# RL7005_IP_SVD register map
Vendor: Realtek
Registers are 32-bit, read-write, reset 0x0 unless marked. A register's access mark holds for its fields unless they carry their own. Offsets are from the block's base; [hi:lo] are bit positions; lines under a group give offsets from that group; {n}, {i} and the like mark numbered series.

## LP_AON
Base 0x4080A000
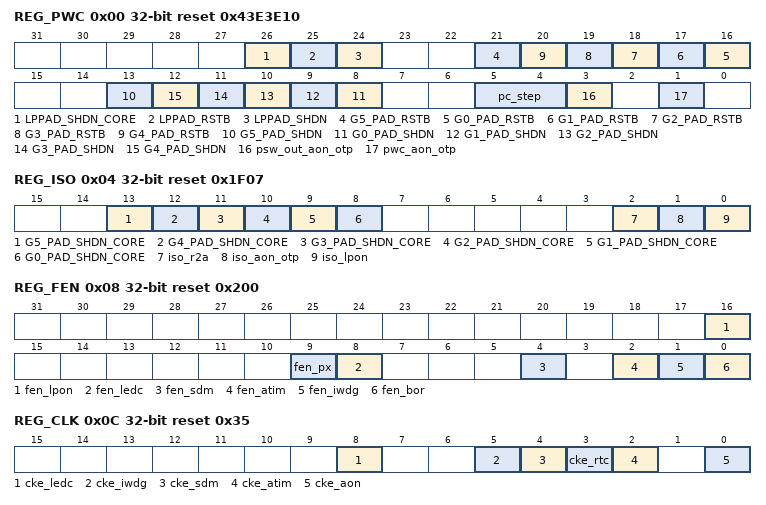
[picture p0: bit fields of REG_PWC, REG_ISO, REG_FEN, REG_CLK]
0x00 REG_PWC access per field reset 0x43E3E10
  [26] LPPAD_SHDN_CORE rw — 1: Release LP PAD SHDN CORE (except G5) 0: Global Assert LP PAD RSTB33 Note:G5 is aon pad, when all LP pad's IO power is ready , aon pmc will release this bit , only in power on init seq .
  [25] LPPAD_RSTB rw — 1: Release LP PAD RSTB33 (except G5) 0: Global Assert LP PAD RSTB33 Note: aon pmc will auto release this bit in power on init seq
  [24] LPPAD_SHDN rw — 1: Global Enable LP PAD (except G5) 0: Shutdown LP PAD Note: aon pmc will auto release this bit in power on init seq
  [21] G5_PAD_RSTB rw — 1: Enable G5 group pad 0: Reset PAD Note: This is AON pad group, direct connect to G5 pad, aon pmc will auto release this bit in power on init seq
  [n+16] G{n}_PAD_RSTB rw (n=0..4) — 1: Enable G{n} group pad 0: Reset PAD
  [13] G5_PAD_SHDN rw — 1: Enable G5 group pad 0: Shutdown PAD Note: This is AON pad group, aon pmc will auto release this bit in power on init seq
  [n+8] G{n}_PAD_SHDN rw (n=0..4) — 1: Enable G{n} group pad 0: Shutdown PAD
  [5:4] pc_step rw — power cut enable time step. 0: not valid 1: 10us 2: 20us 3: 30us
  [3] psw_out_aon_otp ro — aon otp domain power switch status 1: power on 0: power off
  [1] pwc_aon_otp rw — OTP power cut enable for core power, high active. 1:enable 0:disable
0x04 REG_ISO reset 0x1F07
  [13] G5_PAD_SHDN_CORE — 1: Enable G5 group pad 0: Shutdown PAD Note: This maybe nouse , for AON pad , IO power always on before core power.
  [12] G4_PAD_SHDN_CORE — 1: Enable G4 group pad 0: Shutdown PAD
  [11] G3_PAD_SHDN_CORE — 1: Enable G3 group pad 0: Shutdown PAD
  [10] G2_PAD_SHDN_CORE — 1: Enable G2 group pad 0: Shutdown PAD
  [9] G1_PAD_SHDN_CORE — 1: Enable G1 group pad 0: Shutdown PAD Note:default is shutdown, wait pmc enable MLDO power
  [8] G0_PAD_SHDN_CORE — 1: Enable G0 group pad 0: Shutdown PAD It will be deassert by aon_det_rtc automaticly
  [2] iso_r2a — 1: ISO signals from RTC to AON 0: Release
  [1] iso_aon_otp — 1: ISO signals from otp core power domain 0: Release
  [0] iso_lpon — When LDO core power on, PD_LPON is on. 1: ISO signal of LPON power domain 0: Release
0x08 REG_FEN reset 0x200
  [16] fen_lpon — LS global reset 1: Enable LS function 0: Disable
  [9] fen_px — 1: Enable pad interface function 0: Disable Note: this module is in syson power domain
  [8] fen_ledc — 1: Enable led display function 0: Disable Note: this module is in syson power domain
  [4] fen_sdm — 1: Enable 32.768K SDM function 0: Disable
  [2] fen_atim — 1: Enable AON timer 0: Reset AON timer Note: AON timer starts to run only when event happens.
  [1] fen_iwdg — 1: Enable IWDG by HW autoload. Once enabled, IWDG can't be disabled unless por asserts.
  [0] fen_bor — Enable bor reset function, default is 0 when power on
0x0C REG_CLK reset 0x35
  [8] cke_ledc — 1: Enable ledc module's clock 0: Disable
  [5] cke_iwdg — 1: Enable iwdg bus clock 0: Disable
  [4] cke_sdm — 1: Enable 32.768K SDM module's clock 0: Disable
  [3] cke_rtc — 1: Enable RTC clock 0: Disable
  [2] cke_atim — 1: Enable AON timer clock 0: Disable
  [0] cke_aon — if 0, aon reg(except this bit) , swr/ldo reg will be gated. Note: AON clock can't be shutdown as analog need.
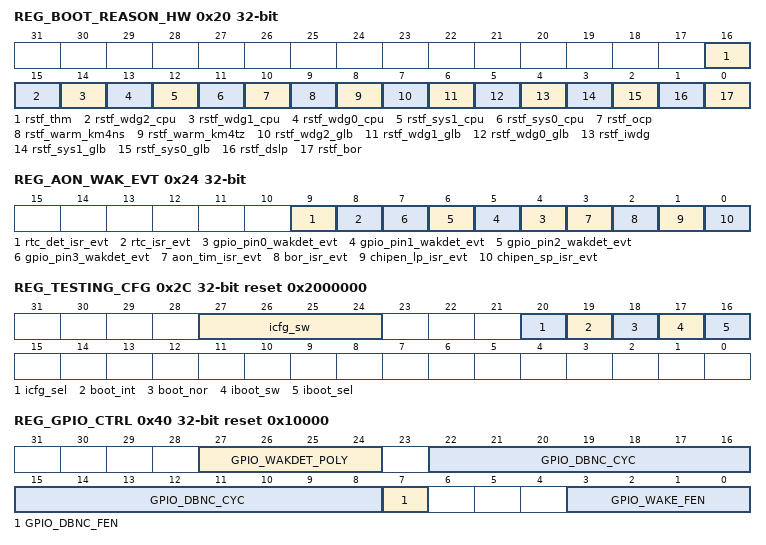
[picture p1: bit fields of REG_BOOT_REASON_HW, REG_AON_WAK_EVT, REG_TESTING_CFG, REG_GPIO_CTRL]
0x20 REG_BOOT_REASON_HW ro
  [16] rstf_thm — This bit will be set to 1 when Thermal resets the system. Write 1 to clear.
  [15] rstf_wdg2_cpu — This bit will be set to 1 when WDG resets local CPU only. Write 1 to clear.
  [14] rstf_wdg1_cpu — This bit will be set to 1 when WDG resets local CPU only. Write 1 to clear.
  [13] rstf_wdg0_cpu — This bit will be set to 1 when WDG resets local CPU only. Write 1 to clear.
  [12] rstf_sys1_cpu — This bit will be set to 1 when cpu1 resets local CPU. Write 1 to clear.
  [11] rstf_sys0_cpu — This bit will be set to 1 when cpu0 resets local CPU. Write 1 to clear.
  [10] rstf_ocp — This bit will be set to 1 when OCP happen, it will let system enter dslp mode. Write 1 to clear.
  [9] rstf_warm_km4ns — This bit will be set to 1 when kr4 warm resets the system. Write 1 to clear.
  [8] rstf_warm_km4tz — This bit will be set to 1 when km4 warm resets the system. Write 1 to clear.
  [7] rstf_wdg2_glb — This bit will be set to 1 when WDG resets the system. Write 1 to clear.
  [6] rstf_wdg1_glb — This bit will be set to 1 when WDG resets the system. Write 1 to clear.
  [5] rstf_wdg0_glb — This bit will be set to 1 when WDG resets the system. Write 1 to clear.
  [4] rstf_iwdg — This bit will be set to 1 when WDG resets the system. Write 1 to clear.
  [3] rstf_sys1_glb — This bit will be set to 1 when cpu1 resets the system. Write 1 to clear.
  [2] rstf_sys0_glb — This bit will be set to 1 when cpu0 resets the system. Write 1 to clear.
  [1] rstf_dslp — This is boot reason for dslp exit, clear by SW write to 1.
  [0] rstf_bor — This bit will be set to 1 when BOR resets the system. Write 1 to clear.
0x24 REG_AON_WAK_EVT ro
  [9] rtc_det_isr_evt — RTC domain 131k detect interrupt wake event occurs.
  [8] rtc_isr_evt — RTC function interrupt wake event occurs.
  [n+4] gpio_pin{n}_wakdet_evt (n=0..3) — Wake event for wake pin{n} 1: wake event detected 0: no wake event Note: aon gpio only used to wake hw pmc, to interrupt SW, it must enable GPIO interrupt in LP GPIO IP, and the poly must be same as AON GPIO setting.
  [3] aon_tim_isr_evt — AON timer interrupt event occurs.
  [2] bor_isr_evt — bor interrupt event occurs.
  [1] chipen_lp_isr_evt — Chipen long press interrupt event occurs.
  [0] chipen_sp_isr_evt — Chipen short press interrupt event occurs.
0x2C REG_TESTING_CFG reset 0x2000000
  [27:24] icfg_sw — icfg configured by SIC/SW
  [20] icfg_sel — If 1, using icfg_sw to replace trapped icfg value.
  [19] boot_int — config by SW, boot from internal MCM flash
  [18] boot_nor — config by SW, boot from external
  [17] iboot_sw — No use
  [16] iboot_sel — If 1, using boot_int or boot_nor to replace trapped iboot value.
0x30 REG_TIM_CNT ro
  [31:0] aon_tim_cnt_cur — Aon timer current count value.
0x34 REG_TIM_SET
  [31:0] aon_tim_cnt_set — Set aon time a countdown value, when timer count down, it will trigger a aon_tim event.
0x38 REG_TIM_IER
  [0] AON_TIM_IE — Timer interrupt enable 0:disable 1:enable
0x3C REG_TIM_ISR ro
  [0] AON_TIM_ISR — Timer interrupt status 0:no interrupt 1:interrupt occurs
0x40 REG_GPIO_CTRL reset 0x10000
  [27:24] GPIO_WAKDET_POLY — Wake pin polarity 0: low active 1: high active bit1: wake pin1 polarity bit0: wake pin0 polarity Note: once a wake pin is set, the pads PU/PD will be force by this poly value, and soft config have no use.
  [22:8] GPIO_DBNC_CYC — The GPIO signal will be filtered by the number of debounce cycles of specified in this register. (100k/128k)
  [7] GPIO_DBNC_FEN — 1: Enable gpio debouncer function 0: Disable Default disable for simualtion issue
  [3:0] GPIO_WAKE_FEN — 1: Enable wake pin function 0: Disable Every GPIO has its own enable. When aon pmc is not in DSLP, wake pins will not effect PMC state althrougth this bit is set.
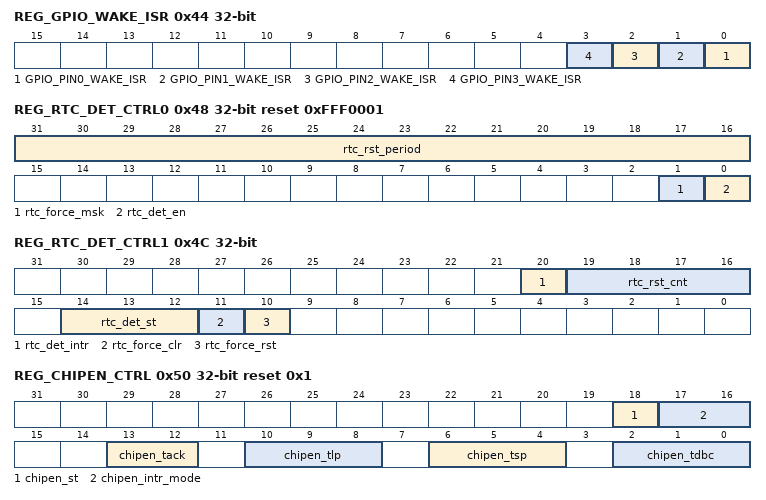
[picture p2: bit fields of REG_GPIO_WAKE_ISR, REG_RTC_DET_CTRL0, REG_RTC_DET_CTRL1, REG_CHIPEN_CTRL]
0x44 REG_GPIO_WAKE_ISR ro
  [n] GPIO_PIN{n}_WAKE_ISR (n=0..3) — Wake pin{n} interrupt status 0:no interrupt 1:interrupt occurs
0x48 REG_RTC_DET_CTRL0 reset 0xFFF0001
  [31:16] rtc_rst_period — Aon det rtc module will periodic send reset seq to RTC if no 131k detect, base on 100K cycle. The period is (this valie + 1)*10us
  [1] rtc_force_msk — Software control to send a reset sequence to RTC domain mask bit. 1: force_rst/force_clr register will be valid 0: force_rst/force_clr register is invalid
  [0] rtc_det_en — AON detect RTC 131k to see RTC domain is abnormal function enable . 1:enable 0:disable
0x4C REG_RTC_DET_CTRL1 access per field
  [20] rtc_det_intr ro — Every time 131k re-detected , it will raise aon interrup . write 1'b1 will clear this value
  [19:16] rtc_rst_cnt ro — It indicates How many times aon send reset sequence to RTC. write 4'b1 will clear this value
  [14:12] rtc_det_st ro — Aon det rtc state machine flag, just for debug
  [11] rtc_force_clr rw — Software control to send a iso clear sequence to RTC domain . It will auto clear to 0
  [10] rtc_force_rst rw — Software control to send a reset sequence to RTC domain . It will auto clear to 0
0x50 REG_CHIPEN_CTRL access per field reset 0x1
  [18] chipen_st ro — CHIP_EN pin status 0: logic '0' on CHIP_EN pin 1: logic '1' on CHIP_EN pin
  [17:16] chipen_intr_mode rw — Chipen operation mode. 00: reset mode. When chipen pad low, hw will reset all chip 01: interrup mode. It will enable short/long press function. 1X: pulse reset mode. The transation from other value to 2'd2 will gen a posedge to set RST_PULSE_EN in HV domain. Once in pulse reset mode , this field can't be modified again , and always read out 2'b11
  [13:12] chipen_tack rw — 00: 50ms 01: 100ms 10: 200ms 11: 400ms
  [10:8] chipen_tlp rw — 000: 1000ms 001: 1500ms 010: 2000ms 011: 2500ms 100: 3000ms 101: 3500ms 110: 4000ms 111: 4500ms
  [6:4] chipen_tsp rw — 000: 0ms 001: 50ms 010: 100ms 011: 150ms 100: 200ms 101: 250ms 110: 300ms 111: 350ms
  [2:0] chipen_tdbc rw — 000: 0us 001: 100us 010: 500us 011: 1000us 100: 2000us 101: 4000us 110: 8000us 111: 16000us
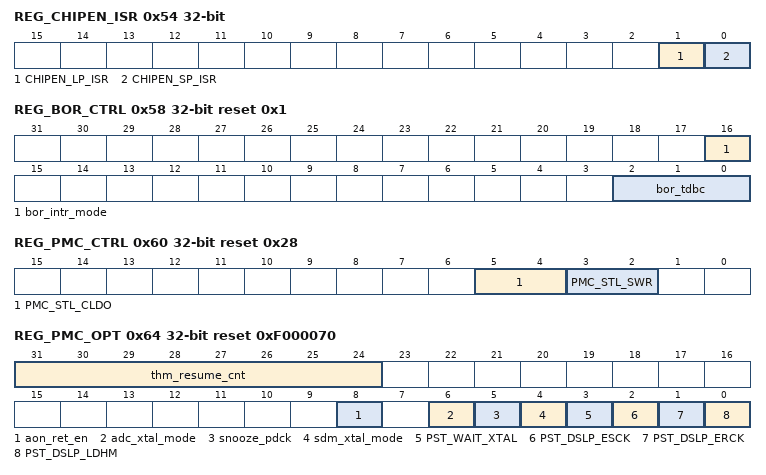
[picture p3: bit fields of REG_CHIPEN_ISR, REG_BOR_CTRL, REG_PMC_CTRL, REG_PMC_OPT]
0x54 REG_CHIPEN_ISR ro
  [1] CHIPEN_LP_ISR — chipen long press interrupt status 0:no interrupt 1:interrupt occurs
  [0] CHIPEN_SP_ISR — chipen short press interrupt status 0:no interrupt 1:interrupt occurs
0x58 REG_BOR_CTRL reset 0x1
  [16] bor_intr_mode — BOR operation mode. 0: reset mode. When analog detect bor, hw will trigger a bor reset. 1: interrup mode. It will raise an interrup first. If this bit set to 0, then trigger a bor reset.
  [2:0] bor_tdbc — 000: 0us 001: 100us 010: 500us 011: 1000us 100: 2000us 101: 4000us 110: 8000us 111: 16000us
0x5C REG_BOR_ISR ro
  [0] BOR_ISR — BOR interrupt status 0:no interrupt 1:interrupt occurs
0x60 REG_PMC_CTRL reset 0x28
  [5:4] PMC_STL_CLDO — wait time for core LDO stable 0: 8*T (T = 10us) 1: 16*T 2: 32*T 3: 64*T
  [3:2] PMC_STL_SWR — wait time for SWR stable 0: 64*T (T = 10us) 1: 128*T 2: 256*T 3: 512*T
0x64 REG_PMC_OPT reset 0xF000070
  [31:24] thm_resume_cnt — After thermal reset happen , it will wait a timer then reboot itself . This count unit in 0.65ms
  [8] aon_ret_en — Option if aon enter retention mode when DSLP, to save more power 1: when enter to DSLP , aon pmc will shutdown more power 0: as before
  [6] adc_xtal_mode — Select xtal mode when xtal used for adc/ctc/comp. 1: Normal 0: LPS
  [5] snooze_pdck — Select xtal auto pdck function for sdm calibration use xtal lps mode 1:Enable 0:Disable
  [4] sdm_xtal_mode — Select xtal mode when xtal used for sdm calibration. 1: Normal 0: LPS
  [3] PST_WAIT_XTAL — 1: When POF , polling xtal invalid signal and then run forward 0: not polling xtal invalid
  [2] PST_DSLP_ESCK — 1: Enable all sdm132k/rtc32k clock when PMC enter deep-sleep mode 0: Gating part of sdm132k/rtc32k to save power when enter deep sleep
  [1] PST_DSLP_ERCK — 1: Enable 100K clock for AON register access when PMC enter deep-sleep mode 0: Disable Note: Default not used , pmc patch may use it
  [0] PST_DSLP_LDHM — 1: Enable AON LDO enter into sleep mode when PMC enter deep-sleep mode 0: Disable Note: Default not used , pmc patch may use it
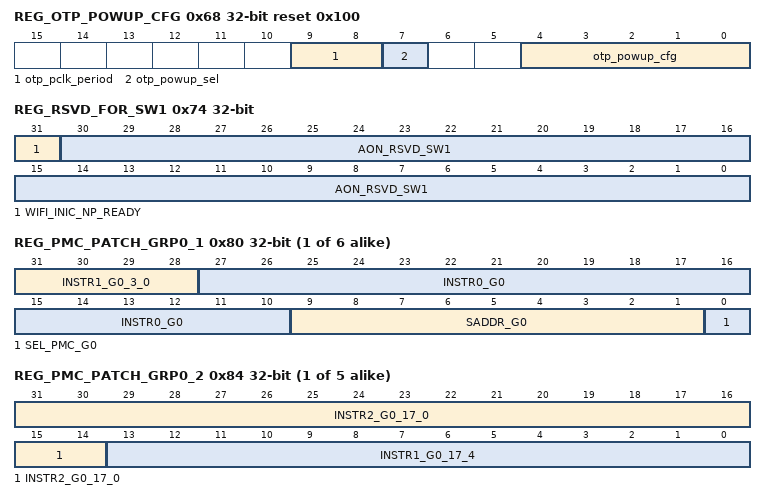
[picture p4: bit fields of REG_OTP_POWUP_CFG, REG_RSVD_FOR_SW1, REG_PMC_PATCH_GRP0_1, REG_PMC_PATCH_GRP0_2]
0x68 REG_OTP_POWUP_CFG reset 0x100
  [9:8] otp_pclk_period — it is used for otp PCLK period when read operation. it need >=25ns.it is timed by cnt under otp clk. for example . when otp_clk is 4MHz: 0:250ns,meet the require 1:500ns,meet the require
  [7] otp_powup_sel — select otp pow up flow is inside control or outside control 0: inside 1: outside
  [4:0] otp_powup_cfg — [0] : penvddr2 [1]: pldo [2]: pdstb [3]: ptrim [4]: pce
0x74 REG_RSVD_FOR_SW1
  [31] WIFI_INIC_NP_READY — Wi-Fi NP initialization ready flag
  [30:0] AON_RSVD_SW1
{0x80+8i} REG_PMC_PATCH_GRP{i}_1 (i=0..5)
  [31:28] INSTR1_G{i}_3_0 — Instruction1 of AON PMC patch group{i}
  [27:10] INSTR0_G{i} — Instruction0 of AON PMC patch group{i}
  [9:1] SADDR_G{i} — Start address of the first instruction of AON PMC patch group0
  [0] SEL_PMC_G{i} — Select PMC for this patch group 0:aon pmc 1:regu pmc
{0x84+8i} REG_PMC_PATCH_GRP{i}_2 (i=0..4)
  [31:14] INSTR2_G{i}_17_0 — Instruction2 of AON PMC patch group{i}
  [13:0] INSTR1_G{i}_17_4 — Instruction1 of AON PMC patch group{i}
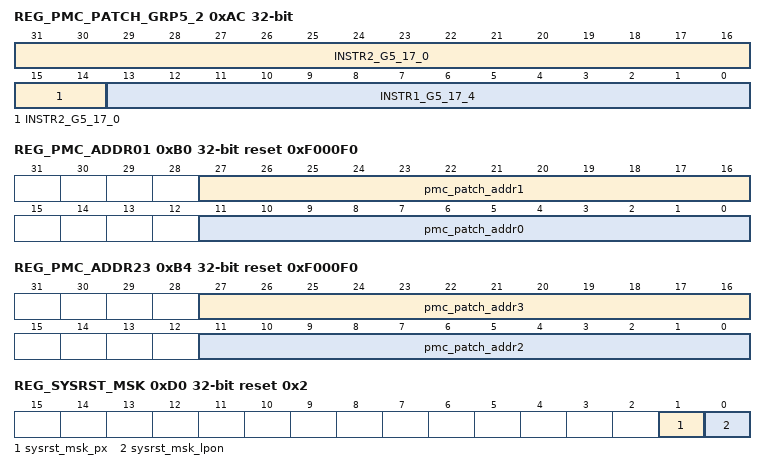
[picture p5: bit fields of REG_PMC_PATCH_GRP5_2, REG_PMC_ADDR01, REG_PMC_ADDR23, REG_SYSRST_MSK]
0xAC REG_PMC_PATCH_GRP5_2
  [31:14] INSTR2_G5_17_0 — HW used only , these are for pmc patch Note: regu reg 0xF0 must not be used
  [13:0] INSTR1_G5_17_4 — HW used only , these are for pmc patch
0xB0 REG_PMC_ADDR01 reset 0xF000F0
  [27:16] pmc_patch_addr1 — HW used only , these are for pmc patch
  [11:0] pmc_patch_addr0 — HW used only , these are for pmc patch Note: these addrs are shared by aon_pmc and regu_pmc
0xB4 REG_PMC_ADDR23 reset 0xF000F0
  [27:16] pmc_patch_addr3 — HW used only , these are for pmc patch
  [11:0] pmc_patch_addr2 — HW used only , these are for pmc patch
0xB8 REG_PMC_DBG_FLAG
  [7:0] regu_pmc_flag_pc — PMC will raise a debug flag if hw pmc pc value hit this value
0xD0 REG_SYSRST_MSK reset 0x2
  [1] sysrst_msk_px — Peri global reset 1: mask pinmux and led pro reset when sys reset happen 0: reset by sys reset
  [0] sysrst_msk_lpon — Lpon global reset 1: mask LS reset when sys reset happen 0: reset by sys reset
0xE0 REG_AON_BACKUP0
  [31:0] aon_bk0 — Note , those bits are shared for RTC domain test used as shift in pattern
{0xE0+4i} REG_AON_BACKUP{i} (i=1..3)
  [31:0] aon_bk{i}
0xF0 REG_BOUNDARY_CHK reset 0xBDC00512
  [31:0] dummy — HW used only . Used for access boundary check, AON is 256B which is 000-FF
0xF8 REG_DUMMY_AIP_CTRL0 reset 0xF
  [7:0] aip_ctrl_rsvd0 — reserved for aip control
0xFC REG_DUMMY_AIP_INFO0 ro
  [7:0] aip_info_rsvd0 — reserved for aip info indication
